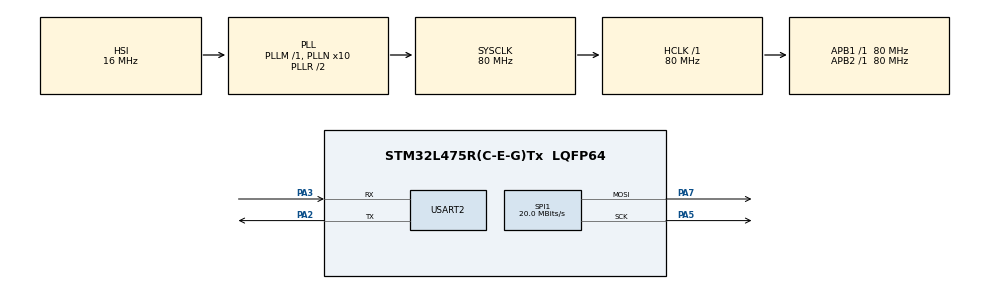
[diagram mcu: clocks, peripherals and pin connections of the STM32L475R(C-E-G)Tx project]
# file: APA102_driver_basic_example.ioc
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Dma.Request0=SPI1_TX
Dma.SPI1_TX.0.Direction=DMA_MEMORY_TO_PERIPH
Dma.SPI1_TX.0.Instance=DMA1_Channel3
Dma.SPI1_TX.0.MemDataAlignment=DMA_MDATAALIGN_BYTE
Dma.SPI1_TX.0.MemInc=DMA_MINC_ENABLE
Dma.SPI1_TX.0.Mode=DMA_NORMAL
Dma.SPI1_TX.0.PeriphDataAlignment=DMA_PDATAALIGN_BYTE
Dma.SPI1_TX.0.PeriphInc=DMA_PINC_DISABLE
Dma.SPI1_TX.0.Priority=DMA_PRIORITY_LOW
Mcu.Family=STM32L4
Mcu.Name=STM32L475R(C-E-G)Tx
Mcu.Package=LQFP64
NVIC.DMA1_Channel3_IRQn=true\:0\:0\:false\:false\:true\:false\:true\:true
NVIC.PriorityGroup=NVIC_PRIORITYGROUP_4
NVIC.TIM1_UP_TIM16_IRQn=true\:15\:0\:false\:false\:true\:false\:true\:true
NVIC.TimeBase=TIM1_UP_TIM16_IRQn
NVIC.TimeBaseIP=TIM1
PA2.Mode=Asynchronous
PA2.Signal=USART2_TX
PA3.Mode=Asynchronous
PA3.Signal=USART2_RX
PA5.Mode=TX_Only_Simplex_Unidirect_Master
PA5.Signal=SPI1_SCK
PA7.Mode=TX_Only_Simplex_Unidirect_Master
PA7.Signal=SPI1_MOSI
ProjectManager.HeapSize=0x200
ProjectManager.StackSize=0x400
ProjectManager.TargetToolchain=STM32CubeIDE
RCC.ADCFreq_Value=64000000
RCC.AHBFreq_Value=80000000
RCC.APB1Freq_Value=80000000
RCC.APB1TimFreq_Value=80000000
RCC.APB2Freq_Value=80000000
RCC.APB2TimFreq_Value=80000000
RCC.CortexFreq_Value=80000000
RCC.HCLKFreq_Value=80000000
RCC.HSE_VALUE=8000000
RCC.HSI_VALUE=16000000
RCC.LSE_VALUE=32768
RCC.MSI_VALUE=4000000
RCC.PLLN=10
RCC.PLLSourceVirtual=RCC_PLLSOURCE_HSI
RCC.SYSCLKFreq_VALUE=80000000
RCC.SYSCLKSource=RCC_SYSCLKSOURCE_PLLCLK
RCC.USBFreq_Value=64000000
RCC.VCOOutputFreq_Value=160000000
SPI1.BaudRatePrescaler=SPI_BAUDRATEPRESCALER_4
SPI1.CLKPhase=SPI_PHASE_2EDGE
SPI1.CLKPolarity=SPI_POLARITY_HIGH
SPI1.CalculateBaudRate=20.0 MBits/s
SPI1.DataSize=SPI_DATASIZE_8BIT
SPI1.Direction=SPI_DIRECTION_2LINES
SPI1.Mode=SPI_MODE_MASTER
SPI1.VirtualType=VM_MASTER
USART2.VirtualMode-Asynchronous=VM_ASYNC
VP_SYS_VS_tim1.Mode=TIM1
board=custom

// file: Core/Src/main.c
/* USER CODE BEGIN Header */
/**
  ******************************************************************************
  * @file           : main.c
  * @brief          : Main program body
  ******************************************************************************
  * @attention
  *
  * Copyright (c) 2024 STMicroelectronics.
  * All rights reserved.
  *
  * This software is licensed under terms that can be found in the LICENSE file
  * in the root directory of this software component.
  * If no LICENSE file comes with this software, it is provided AS-IS.
  *
  ******************************************************************************
  */
/* USER CODE END Header */
#include "main.h"
#include "dma.h"
#include "spi.h"
#include "usart.h"
#include "gpio.h"

/* USER CODE BEGIN Includes */
#include "main_cpp.h"
/* USER CODE END Includes */

void SystemClock_Config(void);

int main(void)
{

  /* MCU Configuration--------------------------------------------------------*/

  /* Reset of all peripherals, Initializes the Flash interface and the Systick. */
  HAL_Init();

  /* Configure the system clock */
  SystemClock_Config();

  /* Initialize all configured peripherals */
  MX_GPIO_Init();
  MX_DMA_Init();
  MX_SPI1_Init();
  MX_USART2_UART_Init();
  /* USER CODE BEGIN 2 */
  //jump into cpp program
  cpp_main();
  /* USER CODE END 2 */

  /* Infinite loop */
  while (1)
  {

  }
}

void SystemClock_Config(void)
{
  RCC_OscInitTypeDef RCC_OscInitStruct = {0};
  RCC_ClkInitTypeDef RCC_ClkInitStruct = {0};

  /** Configure the main internal regulator output voltage
  */
  if (HAL_PWREx_ControlVoltageScaling(PWR_REGULATOR_VOLTAGE_SCALE1) != HAL_OK)
  {
    Error_Handler();
  }

  /** Initializes the RCC Oscillators according to the specified parameters
  * in the RCC_OscInitTypeDef structure.
  */
  RCC_OscInitStruct.OscillatorType = RCC_OSCILLATORTYPE_HSI;
  RCC_OscInitStruct.HSIState = RCC_HSI_ON;
  RCC_OscInitStruct.HSICalibrationValue = RCC_HSICALIBRATION_DEFAULT;
  RCC_OscInitStruct.PLL.PLLState = RCC_PLL_ON;
  RCC_OscInitStruct.PLL.PLLSource = RCC_PLLSOURCE_HSI;
  RCC_OscInitStruct.PLL.PLLM = 1;
  RCC_OscInitStruct.PLL.PLLN = 10;
  RCC_OscInitStruct.PLL.PLLP = RCC_PLLP_DIV7;
  RCC_OscInitStruct.PLL.PLLQ = RCC_PLLQ_DIV2;
  RCC_OscInitStruct.PLL.PLLR = RCC_PLLR_DIV2;
  if (HAL_RCC_OscConfig(&RCC_OscInitStruct) != HAL_OK)
  {
    Error_Handler();
  }

  /** Initializes the CPU, AHB and APB buses clocks
  */
  RCC_ClkInitStruct.ClockType = RCC_CLOCKTYPE_HCLK|RCC_CLOCKTYPE_SYSCLK
                              |RCC_CLOCKTYPE_PCLK1|RCC_CLOCKTYPE_PCLK2;
  RCC_ClkInitStruct.SYSCLKSource = RCC_SYSCLKSOURCE_PLLCLK;
  RCC_ClkInitStruct.AHBCLKDivider = RCC_SYSCLK_DIV1;
  RCC_ClkInitStruct.APB1CLKDivider = RCC_HCLK_DIV1;
  RCC_ClkInitStruct.APB2CLKDivider = RCC_HCLK_DIV1;

  if (HAL_RCC_ClockConfig(&RCC_ClkInitStruct, FLASH_LATENCY_4) != HAL_OK)
  {
    Error_Handler();
  }
}

void HAL_TIM_PeriodElapsedCallback(TIM_HandleTypeDef *htim)
{
  if (htim->Instance == TIM1) {
    HAL_IncTick();
  }
}

void Error_Handler(void)
{
  __disable_irq();
  while (1)
  {
  }
}
